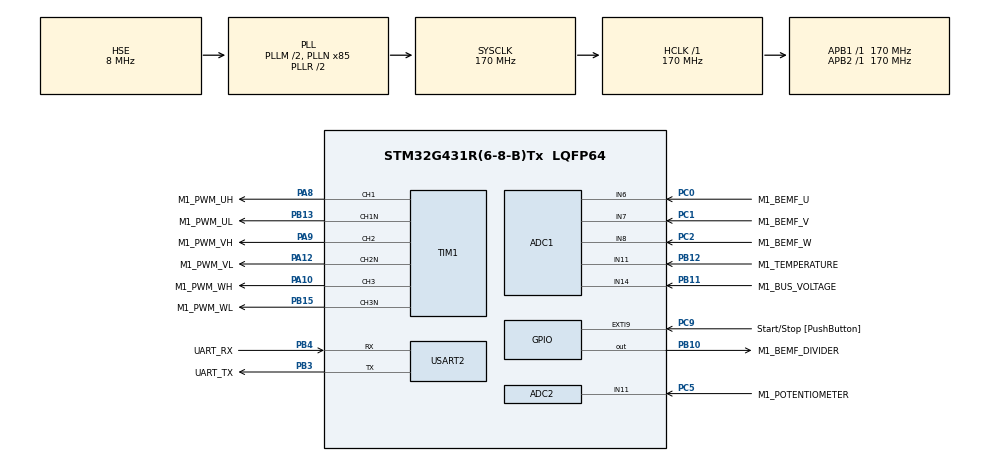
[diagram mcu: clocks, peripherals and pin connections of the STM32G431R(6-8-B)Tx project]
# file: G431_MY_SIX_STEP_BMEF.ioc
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ADC1.Channel-0\#ChannelRegularConversion=ADC_CHANNEL_14
ADC1.Channel-1\#ChannelRegularConversion=ADC_CHANNEL_11
ADC1.ClockPrescaler=ADC_CLOCK_ASYNC_DIV1
ADC1.DataAlign=ADC_DATAALIGN_LEFT
ADC1.EnableAnalogWatchDog1=true
ADC1.EnableInjectedConversion=ENABLE
ADC1.ExternalTrigInjecConv=ADC_EXTERNALTRIGINJEC_T1_TRGO
ADC1.ExternalTrigInjecConvEdge=ADC_EXTERNALTRIGINJECCONV_EDGE_FALLING
ADC1.InjNumberOfConversion=1
ADC1.InjectedChannel-2\#ChannelInjectedConversion=ADC_CHANNEL_6
ADC1.InjectedOffsetNumber-2\#ChannelInjectedConversion=ADC_OFFSET_NONE
ADC1.InjectedRank-2\#ChannelInjectedConversion=1
ADC1.InjectedSamplingTime-2\#ChannelInjectedConversion=ADC_SAMPLETIME_92CYCLES_5
ADC1.NbrOfConversion=2
ADC1.NbrOfConversionFlag=1
ADC1.OffsetNumber-0\#ChannelRegularConversion=ADC_OFFSET_NONE
ADC1.OffsetNumber-1\#ChannelRegularConversion=ADC_OFFSET_NONE
ADC1.Rank-0\#ChannelRegularConversion=1
ADC1.Rank-1\#ChannelRegularConversion=2
ADC1.Rank1_Channel=ADC_CHANNEL_6
ADC1.SamplingTime-0\#ChannelRegularConversion=ADC_SAMPLETIME_47CYCLES_5
ADC1.SamplingTime-1\#ChannelRegularConversion=ADC_SAMPLETIME_47CYCLES_5
ADC1.WatchdogChannel=ADC_CHANNEL_14
ADC1.master=1
ADC2.Channel-0\#ChannelRegularConversion=ADC_CHANNEL_11
ADC2.ClockPrescaler=ADC_CLOCK_ASYNC_DIV1
ADC2.DataAlign=ADC_DATAALIGN_LEFT
ADC2.NbrOfConversionFlag=1
ADC2.OffsetNumber-0\#ChannelRegularConversion=ADC_OFFSET_NONE
ADC2.Rank-0\#ChannelRegularConversion=1
ADC2.SamplingTime-0\#ChannelRegularConversion=ADC_SAMPLETIME_47CYCLES_5
Dma.Request0=USART2_RX
Dma.Request1=USART2_TX
Dma.USART2_RX.0.Direction=DMA_PERIPH_TO_MEMORY
Dma.USART2_RX.0.EventEnable=DISABLE
Dma.USART2_RX.0.Instance=DMA1_Channel1
Dma.USART2_RX.0.MemDataAlignment=DMA_MDATAALIGN_BYTE
Dma.USART2_RX.0.MemInc=DMA_MINC_ENABLE
Dma.USART2_RX.0.Mode=DMA_NORMAL
Dma.USART2_RX.0.PeriphDataAlignment=DMA_PDATAALIGN_BYTE
Dma.USART2_RX.0.PeriphInc=DMA_PINC_DISABLE
Dma.USART2_RX.0.Polarity=HAL_DMAMUX_REQ_GEN_RISING
Dma.USART2_RX.0.Priority=DMA_PRIORITY_LOW
Dma.USART2_RX.0.RequestNumber=1
Dma.USART2_RX.0.SignalID=NONE
Dma.USART2_RX.0.SyncEnable=DISABLE
Dma.USART2_RX.0.SyncPolarity=HAL_DMAMUX_SYNC_NO_EVENT
Dma.USART2_RX.0.SyncRequestNumber=1
Dma.USART2_RX.0.SyncSignalID=NONE
Dma.USART2_TX.1.Direction=DMA_MEMORY_TO_PERIPH
Dma.USART2_TX.1.EventEnable=DISABLE
Dma.USART2_TX.1.Instance=DMA1_Channel2
Dma.USART2_TX.1.MemDataAlignment=DMA_MDATAALIGN_BYTE
Dma.USART2_TX.1.MemInc=DMA_MINC_ENABLE
Dma.USART2_TX.1.Mode=DMA_NORMAL
Dma.USART2_TX.1.PeriphDataAlignment=DMA_PDATAALIGN_BYTE
Dma.USART2_TX.1.PeriphInc=DMA_PINC_DISABLE
Dma.USART2_TX.1.Polarity=HAL_DMAMUX_REQ_GEN_RISING
Dma.USART2_TX.1.Priority=DMA_PRIORITY_LOW
Dma.USART2_TX.1.RequestNumber=1
Dma.USART2_TX.1.SignalID=NONE
Dma.USART2_TX.1.SyncEnable=DISABLE
Dma.USART2_TX.1.SyncPolarity=HAL_DMAMUX_SYNC_NO_EVENT
Dma.USART2_TX.1.SyncRequestNumber=1
Dma.USART2_TX.1.SyncSignalID=NONE
Mcu.Family=STM32G4
Mcu.Name=STM32G431R(6-8-B)Tx
Mcu.Package=LQFP64
NVIC.ADC1_2_IRQn=true\:0\:1\:false\:false\:true\:true\:true\:true
NVIC.DMA1_Channel1_IRQn=true\:3\:0\:true\:false\:true\:true\:true\:true
NVIC.DMA1_Channel2_IRQn=true\:3\:0\:true\:false\:true\:true\:true\:true
NVIC.EXTI9_5_IRQn=true\:3\:0\:true\:false\:true\:true\:true\:true
NVIC.PriorityGroup=NVIC_PRIORITYGROUP_3
NVIC.TIM1_BRK_TIM15_IRQn=true\:1\:0\:true\:false\:true\:true\:true\:true
NVIC.TIM1_UP_TIM16_IRQn=true\:1\:0\:true\:false\:true\:true\:true\:true
NVIC.TIM2_IRQn=true\:0\:0\:false\:false\:true\:true\:true\:true
NVIC.USART2_IRQn=true\:3\:1\:true\:false\:true\:false\:true\:true
PA10.GPIO_Label=M1_PWM_WH
PA10.GPIO_PuPd=GPIO_PULLDOWN
PA10.GPIO_Speed=GPIO_SPEED_FREQ_HIGH
PA10.Signal=S_TIM1_CH3
PA12.GPIO_Label=M1_PWM_VL
PA12.GPIO_PuPd=GPIO_PULLDOWN
PA12.GPIO_Speed=GPIO_SPEED_FREQ_HIGH
PA12.Mode=PWM Generation2 CH2 CH2N
PA12.Signal=TIM1_CH2N
PA13.GPIO_Label=TMS
PA13.Mode=Serial_Wire
PA13.Signal=SYS_JTMS-SWDIO
PA14.GPIO_Label=TCK
PA14.Mode=Serial_Wire
PA14.Signal=SYS_JTCK-SWCLK
PA8.GPIO_Label=M1_PWM_UH
PA8.GPIO_PuPd=GPIO_PULLDOWN
PA8.GPIO_Speed=GPIO_SPEED_FREQ_HIGH
PA8.Signal=S_TIM1_CH1
PA9.GPIO_Label=M1_PWM_VH
PA9.GPIO_PuPd=GPIO_PULLDOWN
PA9.GPIO_Speed=GPIO_SPEED_FREQ_HIGH
PA9.Signal=S_TIM1_CH2
PB10.GPIO_Label=M1_BEMF_DIVIDER
PB10.GPIO_PuPd=GPIO_PULLDOWN
PB10.Signal=GPIO_Output
PB11.GPIO_Label=M1_BUS_VOLTAGE
PB11.Mode=IN14-Single-Ended
PB11.Signal=ADC1_IN14
PB12.GPIO_Label=M1_TEMPERATURE
PB12.Mode=IN11-Single-Ended
PB12.Signal=ADC1_IN11
PB13.GPIO_Label=M1_PWM_UL
PB13.GPIO_PuPd=GPIO_PULLDOWN
PB13.GPIO_Speed=GPIO_SPEED_FREQ_HIGH
PB13.Mode=PWM Generation1 CH1 CH1N
PB13.Signal=TIM1_CH1N
PB15.GPIO_Label=M1_PWM_WL
PB15.GPIO_PuPd=GPIO_PULLDOWN
PB15.GPIO_Speed=GPIO_SPEED_FREQ_HIGH
PB15.Mode=PWM Generation3 CH3 CH3N
PB15.Signal=TIM1_CH3N
PB3.GPIO_Label=UART_TX
PB3.Mode=Asynchronous
PB3.Signal=USART2_TX
PB4.GPIO_Label=UART_RX
PB4.Mode=Asynchronous
PB4.Signal=USART2_RX
PC0.GPIO_Label=M1_BEMF_U
PC0.Mode=IN6-Single-Ended
PC0.Signal=ADC1_IN6
PC1.GPIO_Label=M1_BEMF_V
PC1.Mode=IN7-Single-Ended
PC1.Signal=ADC1_IN7
PC2.GPIO_Label=M1_BEMF_W
PC2.Mode=IN8-Single-Ended
PC2.Signal=ADC1_IN8
PC5.GPIO_Label=M1_POTENTIOMETER
PC5.Mode=IN11-Single-Ended
PC5.Signal=ADC2_IN11
PC9.GPIO_Label=Start/Stop [PushButton]
PC9.Signal=GPXTI9
PF0-OSC_IN.Mode=HSE-External-Oscillator
PF0-OSC_IN.Signal=RCC_OSC_IN
PF1-OSC_OUT.Mode=HSE-External-Oscillator
PF1-OSC_OUT.Signal=RCC_OSC_OUT
ProjectManager.HeapSize=0x200
ProjectManager.StackSize=0x400
ProjectManager.TargetToolchain=MDK-ARM V5.32
RCC.ADC12CLockSelection=RCC_ADC12CLKSOURCE_PLL
RCC.ADC12Freq_Value=42500000
RCC.AHBFreq_Value=170000000
RCC.APB1Freq_Value=170000000
RCC.APB1TimFreq_Value=170000000
RCC.APB2Freq_Value=170000000
RCC.APB2TimFreq_Value=170000000
RCC.CortexFreq_Value=170000000
RCC.EXTERNAL_CLOCK_VALUE=12288000
RCC.HCLKFreq_Value=170000000
RCC.HSE_VALUE=8000000
RCC.HSI48_VALUE=48000000
RCC.HSI_VALUE=16000000
RCC.LSE_VALUE=32768
RCC.PLLM=RCC_PLLM_DIV2
RCC.PLLN=85
RCC.PLLP=RCC_PLLP_DIV8
RCC.PLLSourceVirtual=RCC_PLLSOURCE_HSE
RCC.SYSCLKFreq_VALUE=170000000
RCC.SYSCLKSource=RCC_SYSCLKSOURCE_PLLCLK
RCC.USBFreq_Value=170000000
RCC.VCOOutputFreq_Value=340000000
SH.S_TIM1_CH1.0=TIM1_CH1,PWM Generation1 CH1 CH1N
SH.S_TIM1_CH2.0=TIM1_CH2,PWM Generation2 CH2 CH2N
SH.S_TIM1_CH3.0=TIM1_CH3,PWM Generation3 CH3 CH3N
TIM1.Break2Filter=3
TIM1.Channel-PWM\ Generation1\ CH1\ CH1N=TIM_CHANNEL_1
TIM1.Channel-PWM\ Generation2\ CH2\ CH2N=TIM_CHANNEL_2
TIM1.Channel-PWM\ Generation3\ CH3\ CH3N=TIM_CHANNEL_3
TIM1.Channel-PWM\ Generation4\ No\ Output=TIM_CHANNEL_4
TIM1.DeadTime=((DEAD_TIME_COUNTS) / 2)
TIM1.PeriodNoDither=(PWM_PERIOD_CYCLES)
TIM1.Prescaler=((TIM_CLOCK_DIVIDER) - 1)
TIM1.RepetitionCounter=(REP_COUNTER)
TIM1.TIM_MasterOutputTrigger=TIM_TRGO_OC4REF
TIM2.PeriodNoDither=LF_TIMER_ARR
TIM2.Prescaler=LF_TIMER_PSC
TIM2.TIM_MasterOutputTrigger=TIM_TRGO_ENABLE
TIM2.TIM_MasterSlaveMode=TIM_MASTERSLAVEMODE_ENABLE
USART2.VirtualMode-Asynchronous=VM_ASYNC
VP_SYS_VS_DBSignals.Mode=DisableDeadBatterySignals
VP_TIM1_VS_ClockSourceINT.Mode=Internal
VP_TIM1_VS_no_output4.Mode=PWM Generation4 No Output
VP_TIM2_VS_ClockSourceINT.Mode=Internal
board=custom

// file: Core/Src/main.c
/* USER CODE BEGIN Header */
/**
  ******************************************************************************
  * @file           : main.c
  * @brief          : Main program body
  ******************************************************************************
  * @attention
  *
  * Copyright (c) 2026 STMicroelectronics.
  * All rights reserved.
  *
  * This software is licensed under terms that can be found in the LICENSE file
  * in the root directory of this software component.
  * If no LICENSE file comes with this software, it is provided AS-IS.
  *
  ******************************************************************************
  */
/* USER CODE END Header */
#include "main.h"
#include "adc.h"
#include "dma.h"
#include "tim.h"
#include "usart.h"
#include "gpio.h"

/* USER CODE BEGIN Includes */
#include "motor_control.h"
#include "serial_protocol.h"
/* USER CODE END Includes */

void SystemClock_Config(void);

/* USER CODE BEGIN 0 */

/* Motor control configuration */

/* USER CODE END 0 */

int main(void)
{

  /* MCU Configuration--------------------------------------------------------*/

  /* Reset of all peripherals, Initializes the Flash interface and the Systick. */
  HAL_Init();

  /* Configure the system clock */
  SystemClock_Config();

  /* Initialize all configured peripherals */
  MX_GPIO_Init();
  MX_DMA_Init();
  MX_USART2_UART_Init();
  MX_ADC1_Init();
  MX_ADC2_Init();
  MX_TIM1_Init();
  MX_TIM2_Init();

  /* Infinite loop */
  while (1)
  {

  }
  /* USER CODE END 3 */
}

void SystemClock_Config(void)
{
  RCC_OscInitTypeDef RCC_OscInitStruct = {0};
  RCC_ClkInitTypeDef RCC_ClkInitStruct = {0};

  /** Configure the main internal regulator output voltage
  */
  HAL_PWREx_ControlVoltageScaling(PWR_REGULATOR_VOLTAGE_SCALE1_BOOST);

  /** Initializes the RCC Oscillators according to the specified parameters
  * in the RCC_OscInitTypeDef structure.
  */
  RCC_OscInitStruct.OscillatorType = RCC_OSCILLATORTYPE_HSE;
  RCC_OscInitStruct.HSEState = RCC_HSE_ON;
  RCC_OscInitStruct.PLL.PLLState = RCC_PLL_ON;
  RCC_OscInitStruct.PLL.PLLSource = RCC_PLLSOURCE_HSE;
  RCC_OscInitStruct.PLL.PLLM = RCC_PLLM_DIV2;
  RCC_OscInitStruct.PLL.PLLN = 85;
  RCC_OscInitStruct.PLL.PLLP = RCC_PLLP_DIV8;
  RCC_OscInitStruct.PLL.PLLQ = RCC_PLLQ_DIV2;
  RCC_OscInitStruct.PLL.PLLR = RCC_PLLR_DIV2;
  if (HAL_RCC_OscConfig(&RCC_OscInitStruct) != HAL_OK)
  {
    Error_Handler();
  }

  /** Initializes the CPU, AHB and APB buses clocks
  */
  RCC_ClkInitStruct.ClockType = RCC_CLOCKTYPE_HCLK|RCC_CLOCKTYPE_SYSCLK
                              |RCC_CLOCKTYPE_PCLK1|RCC_CLOCKTYPE_PCLK2;
  RCC_ClkInitStruct.SYSCLKSource = RCC_SYSCLKSOURCE_PLLCLK;
  RCC_ClkInitStruct.AHBCLKDivider = RCC_SYSCLK_DIV1;
  RCC_ClkInitStruct.APB1CLKDivider = RCC_HCLK_DIV1;
  RCC_ClkInitStruct.APB2CLKDivider = RCC_HCLK_DIV1;

  if (HAL_RCC_ClockConfig(&RCC_ClkInitStruct, FLASH_LATENCY_4) != HAL_OK)
  {
    Error_Handler();
  }
}

void Error_Handler(void)
{
  __disable_irq();
  while (1)
  {
  }
}
